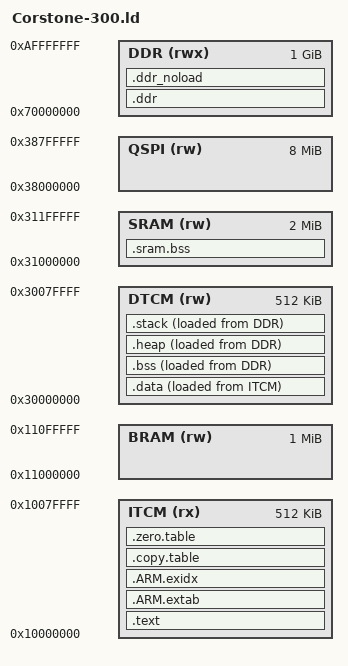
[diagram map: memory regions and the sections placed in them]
/*
 * Copyright 2025 Arm Limited and/or its affiliates.
 *
 * This source code is licensed under the BSD-style license found in the
 * LICENSE file in the root directory of this source tree.
 */

 /*
 * This is a simplified linkerscript for the Corstone-300 memory system.
 * This example has been modified to place certain sections in specific memory.
 * Please refer to the Corstone SSE-300 Technical Reference Manual for
 * further information.
 *
 * https://developer.arm.com/Processors/Corstone-300
 */

__STACK_SIZE = 0x00008000;
__HEAP_SIZE  = 0x00008000;

MEMORY
{
  ITCM  (rx)  : ORIGIN = 0x10000000, LENGTH = 0x00080000
  BRAM  (rw)  : ORIGIN = 0x11000000, LENGTH = 0x00100000
  DTCM  (rw)  : ORIGIN = 0x30000000, LENGTH = 0x00080000
  SRAM  (rw)  : ORIGIN = 0x31000000, LENGTH = 0x00200000
  QSPI  (rw)  : ORIGIN = 0x38000000, LENGTH = 0x00800000
  DDR   (rwx) : ORIGIN = 0x70000000, LENGTH = 0x40000000
}

/* Linker script to place sections and symbol values. Should be used together
 * with other linker script that defines memory regions ITCM and RAM.
 * It references following symbols, which must be defined in code:
 *   Reset_Handler : Entry of reset handler
 *
 * It defines following symbols, which code can use without definition:
 *   __exidx_start
 *   __exidx_end
 *   __copy_table_start__
 *   __copy_table_end__
 *   __zero_table_start__
 *   __zero_table_end__
 *   __etext
 *   __data_start__
 *   __preinit_array_start
 *   __preinit_array_end
 *   __init_array_start
 *   __init_array_end
 *   __fini_array_start
 *   __fini_array_end
 *   __data_end__
 *   __bss_start__
 *   __bss_end__
 *   __end__
 *   end
 *   __HeapLimit
 *   __StackLimit
 *   __StackTop
 *   __stack
 */
ENTRY(Reset_Handler)

SECTIONS
{
  .text :
  {
    KEEP(*(.vectors))
    *(.text*)

    KEEP(*(.init))
    KEEP(*(.fini))

    /* .ctors */
    *crtbegin.o(.ctors)
    *crtbegin?.o(.ctors)
    *(EXCLUDE_FILE(*crtend?.o *crtend.o) .ctors)
    *(SORT(.ctors.*))
    *(.ctors)

    /* .dtors */
    *crtbegin.o(.dtors)
    *crtbegin?.o(.dtors)
    *(EXCLUDE_FILE(*crtend?.o *crtend.o) .dtors)
    *(SORT(.dtors.*))
    *(.dtors)

    *(.rodata*)

    KEEP(*(.eh_frame*))
  } > ITCM

  /*
   * SG veneers:
   * All SG veneers are placed in the special output section .gnu.sgstubs. Its start address
   * must be set, either with the command line option '--section-start' or in a linker script,
   * to indicate where to place these veneers in memory.
   */
/*
  .gnu.sgstubs :
  {
    . = ALIGN(32);
  } > ITCM
*/
  .ARM.extab :
  {
    *(.ARM.extab* .gnu.linkonce.armextab.*)
  } > ITCM

  .ARM.exidx :
  {
  __exidx_start = .;
    *(.ARM.exidx* .gnu.linkonce.armexidx.*)
  __exidx_end = .;
  } > ITCM

  .copy.table :
  {
    . = ALIGN(4);
    __copy_table_start__ = .;

    LONG (LOADADDR(.data))
    LONG (ADDR(.data))
    LONG (SIZEOF(.data) / 4)

    __copy_table_end__ = .;
  } > ITCM

  .zero.table :
  {
    . = ALIGN(4);
    __zero_table_start__ = .;

    LONG (ADDR(.bss))
    LONG (SIZEOF(.bss) / 4)

    __zero_table_end__ = .;

  } > ITCM

  .data : ALIGN(4)
  {
    __data_start__ = .;
    *(vtable)
    *(.data)
    *(.data.*)

    . = ALIGN(4);
    /* preinit data */
    PROVIDE_HIDDEN (__preinit_array_start = .);
    KEEP(*(.preinit_array))
    PROVIDE_HIDDEN (__preinit_array_end = .);

    . = ALIGN(4);
    /* init data */
    PROVIDE_HIDDEN (__init_array_start = .);
    KEEP(*(SORT(.init_array.*)))
    KEEP(*(.init_array))
    PROVIDE_HIDDEN (__init_array_end = .);

    . = ALIGN(4);
    /* finit data */
    PROVIDE_HIDDEN (__fini_array_start = .);
    KEEP(*(SORT(.fini_array.*)))
    KEEP(*(.fini_array))
    PROVIDE_HIDDEN (__fini_array_end = .);

    KEEP(*(.jcr*))
    . = ALIGN(4);
    /* All data end */
    __data_end__ = .;
  } > DTCM AT > ITCM

  .sram.bss (NOLOAD) :
  {
    . = ALIGN(32);
    *(.bss.tensor_arena)
  } > SRAM

  .ddr :
  {
    . = ALIGN(16);
    *(network_model_sec)
    * (.got*)

  } > DDR

  .ddr_noload (NOLOAD) :
  {
    . = ALIGN(16);
    *(input_data_sec)
  } > DDR

  .bss :
  {
    . = ALIGN(4);
    __bss_start__ = .;
    *(.bss)
    *(.bss.*)
    *(COMMON)
    . = ALIGN(4);
    __bss_end__ = .;
  } > DTCM AT > DDR

  .heap (NOLOAD) :
  {
    . = ALIGN(8);
    __end__ = .;
    PROVIDE(end = .);
    . = . + __HEAP_SIZE;
    . = ALIGN(8);
    __HeapLimit = .;
  } > DTCM AT > DDR

  .stack (ORIGIN(DTCM) + LENGTH(DTCM) - __STACK_SIZE) (NOLOAD) :
  {
    . = ALIGN(8);
    __StackLimit = .;
    . = . + __STACK_SIZE;
    . = ALIGN(8);
    __StackTop = .;
  } > DTCM AT > DDR
  PROVIDE(__stack = __StackTop);

  /* Check if data + heap + stack exceeds DTCM limit */
  ASSERT(__StackLimit >= __HeapLimit, "region DTCM overflowed with stack")
}
